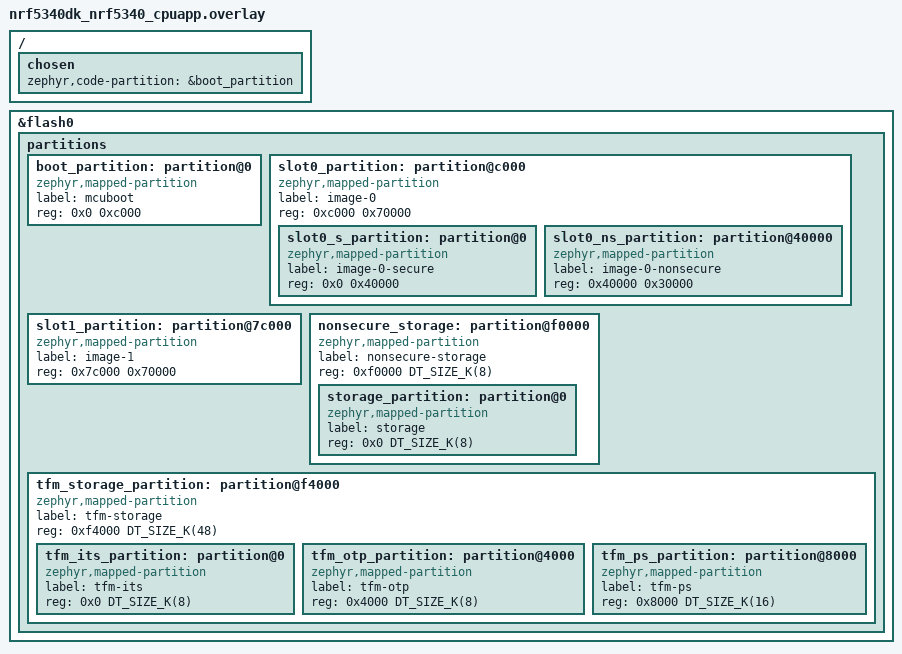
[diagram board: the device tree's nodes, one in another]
/*
 * Copyright (c) 2026 Nordic Semiconductor ASA
 *
 * SPDX-License-Identifier: LicenseRef-Nordic-5-Clause
 */

/ {
	chosen {
		zephyr,code-partition = &boot_partition;
	};
};

/delete-node/ &boot_partition;
/delete-node/ &slot0_partition;
/delete-node/ &slot1_partition;
/delete-node/ &slot0_ns_partition;
/delete-node/ &storage_partition;
/delete-node/ &tfm_its_partition;
/delete-node/ &tfm_otp_partition;
/delete-node/ &tfm_ps_partition;

&flash0 {
	partitions {
		boot_partition: partition@0 {
			compatible = "zephyr,mapped-partition";
			label = "mcuboot";
			reg = <0x0 0xc000>;
		};

		slot0_partition: partition@c000 {
			compatible = "zephyr,mapped-partition";
			label = "image-0";
			reg = <0xc000 0x70000>;
			ranges = <0x0 0xc000 0x70000>;
			#address-cells = <1>;
			#size-cells = <1>;

			slot0_s_partition: partition@0 {
				compatible = "zephyr,mapped-partition";
				label = "image-0-secure";
				reg = <0x0 0x40000>;
			};

			slot0_ns_partition: partition@40000 {
				compatible = "zephyr,mapped-partition";
				label = "image-0-nonsecure";
				reg = <0x40000 0x30000>;
			};
		};

		slot1_partition: partition@7c000 {
			compatible = "zephyr,mapped-partition";
			label = "image-1";
			reg = <0x7c000 0x70000>;
		};

		nonsecure_storage: partition@f0000 {
			compatible = "zephyr,mapped-partition";
			label = "nonsecure-storage";
			reg = <0xf0000 DT_SIZE_K(8)>;
			ranges = <0x0 0xf0000 DT_SIZE_K(8)>;
			#address-cells = <1>;
			#size-cells = <1>;

			storage_partition: partition@0 {
				compatible = "zephyr,mapped-partition";
				label = "storage";
				reg = <0x0 DT_SIZE_K(8)>;
			};
		};

		tfm_storage_partition: partition@f4000 {
			compatible = "zephyr,mapped-partition";
			label = "tfm-storage";
			reg = <0xf4000 DT_SIZE_K(48)>;
			ranges = <0x0 0xf4000 DT_SIZE_K(48)>;
			#address-cells = <1>;
			#size-cells = <1>;

			tfm_its_partition: partition@0 {
				compatible = "zephyr,mapped-partition";
				label = "tfm-its";
				reg = <0x0 DT_SIZE_K(8)>;
			};

			tfm_otp_partition: partition@4000 {
				compatible = "zephyr,mapped-partition";
				label = "tfm-otp";
				reg = <0x4000 DT_SIZE_K(8)>;
			};

			tfm_ps_partition: partition@8000 {
				compatible = "zephyr,mapped-partition";
				label = "tfm-ps";
				reg = <0x8000 DT_SIZE_K(16)>;
			};
		};
	};
};
